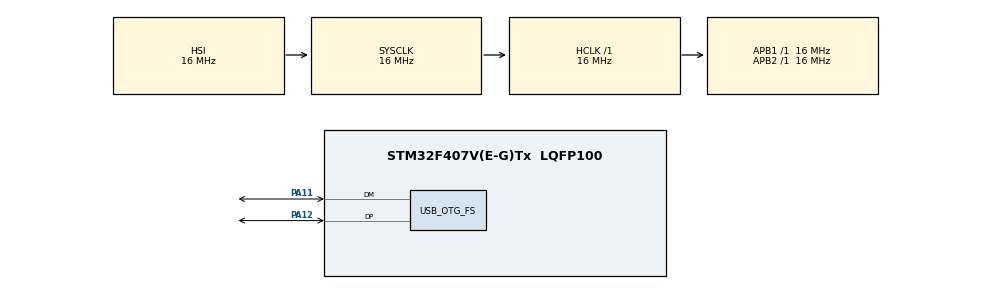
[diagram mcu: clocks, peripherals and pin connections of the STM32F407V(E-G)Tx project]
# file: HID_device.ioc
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Mcu.Family=STM32F4
Mcu.Name=STM32F407V(E-G)Tx
Mcu.Package=LQFP100
NVIC.OTG_FS_IRQn=true\:0\:0\:false\:false\:true
NVIC.PriorityGroup=NVIC_PRIORITYGROUP_4
PA11.Mode=Device_Only
PA11.Signal=USB_OTG_FS_DM
PA12.Mode=Device_Only
PA12.Signal=USB_OTG_FS_DP
PH0-OSC_IN.Mode=HSE-External-Oscillator
PH0-OSC_IN.Signal=RCC_OSC_IN
PH1-OSC_OUT.Mode=HSE-External-Oscillator
PH1-OSC_OUT.Signal=RCC_OSC_OUT
ProjectManager.HeapSize=0x200
ProjectManager.StackSize=0x400
ProjectManager.TargetToolchain=SW4STM32
RCC.48MHZClocksFreq_Value=48000000
RCC.AHBFreq_Value=16000000
RCC.APB1Freq_Value=16000000
RCC.APB2Freq_Value=16000000
RCC.CortexFreq_Value=16000000
RCC.HSE_VALUE=25000000
RCC.HSI_VALUE=16000000
RCC.LSE_VALUE=32768
RCC.PLLM=15
RCC.PLLN=144
RCC.PLLQ=5
RCC.SYSCLKFreq_VALUE=16000000
RCC.VCOOutputFreq_Value=240000000
USB_DEVICE.CLASS_NAME-HID_FS=HID
USB_DEVICE.USBD_HandleTypeDef-HID_FS=hUsbDeviceFS
USB_DEVICE.VirtualMode-HID_FS=Hid
USB_DEVICE.VirtualModeFS=Hid_FS
USB_OTG_FS.VirtualMode=Device_Only
VP_USB_DEVICE_VS_USB_DEVICE_HID_FS.Mode=HID_FS
board=HID_device

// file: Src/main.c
/**
  ******************************************************************************
  * File Name          : main.c
  * Description        : Main program body
  ******************************************************************************
  *
  * COPYRIGHT(c) 2016 STMicroelectronics
  *
  * Redistribution and use in source and binary forms, with or without modification,
  * are permitted provided that the following conditions are met:
  *   1. Redistributions of source code must retain the above copyright notice,
  *      this list of conditions and the following disclaimer.
  *   2. Redistributions in binary form must reproduce the above copyright notice,
  *      this list of conditions and the following disclaimer in the documentation
  *      and/or other materials provided with the distribution.
  *   3. Neither the name of STMicroelectronics nor the names of its contributors
  *      may be used to endorse or promote products derived from this software
  *      without specific prior written permission.
  *
  * THIS SOFTWARE IS PROVIDED BY THE COPYRIGHT HOLDERS AND CONTRIBUTORS "AS IS"
  * AND ANY EXPRESS OR IMPLIED WARRANTIES, INCLUDING, BUT NOT LIMITED TO, THE
  * IMPLIED WARRANTIES OF MERCHANTABILITY AND FITNESS FOR A PARTICULAR PURPOSE ARE
  * DISCLAIMED. IN NO EVENT SHALL THE COPYRIGHT HOLDER OR CONTRIBUTORS BE LIABLE
  * FOR ANY DIRECT, INDIRECT, INCIDENTAL, SPECIAL, EXEMPLARY, OR CONSEQUENTIAL
  * DAMAGES (INCLUDING, BUT NOT LIMITED TO, PROCUREMENT OF SUBSTITUTE GOODS OR
  * SERVICES; LOSS OF USE, DATA, OR PROFITS; OR BUSINESS INTERRUPTION) HOWEVER
  * CAUSED AND ON ANY THEORY OF LIABILITY, WHETHER IN CONTRACT, STRICT LIABILITY,
  * OR TORT (INCLUDING NEGLIGENCE OR OTHERWISE) ARISING IN ANY WAY OUT OF THE USE
  * OF THIS SOFTWARE, EVEN IF ADVISED OF THE POSSIBILITY OF SUCH DAMAGE.
  *
  ******************************************************************************
  */
#include "stm32f4xx_hal.h"
#include "usb_device.h"
#include "gpio.h"

/* USER CODE BEGIN PV */
/* Private variables ---------------------------------------------------------*/

/* USER CODE END PV */

void SystemClock_Config(void);

/* USER CODE BEGIN PFP */
/* Private function prototypes -----------------------------------------------*/

/* USER CODE END PFP */

int main(void)
{

  /* MCU Configuration----------------------------------------------------------*/

  /* Reset of all peripherals, Initializes the Flash interface and the Systick. */
  HAL_Init();

  /* Configure the system clock */
  SystemClock_Config();

  /* Initialize all configured peripherals */
  MX_GPIO_Init();
  MX_USB_DEVICE_Init();

  /* USER CODE BEGIN 2 */
  	  uint8_t i[4];
  /* USER CODE END 2 */

  /* Infinite loop */
  /* USER CODE BEGIN WHILE */
  while (1)
  {
	  i[0]= 0x01;
	 	  i[1]= 0x32;
	 	  i[2]= 0x00;
	 	  i[3]= 0x00;

	 	  USBD_HID_SendReport(&hUsbDeviceFS,i,4);
	  	 HAL_Delay(100);
	  	  i[0]= 0x01;
	  	  i[1]= 0x00;
	  	  i[2]= 0x01;
	  	  i[3]= 0x00;

	  	  USBD_HID_SendReport(&hUsbDeviceFS,i,4);
	  	  HAL_Delay(100);
	  	 	  i[0]= 0x01;
	  	 	  i[1]= 0xCE;
	  	 	  i[2]= 0x00;
	  	 	  i[3]= 0x00;

	  	  USBD_HID_SendReport(&hUsbDeviceFS,i,4);
	  	  HAL_Delay(100);

  /* USER CODE END WHILE */

  }

}

/** System Clock Configuration
*/
void SystemClock_Config(void)
{

  RCC_OscInitTypeDef RCC_OscInitStruct;
  RCC_ClkInitTypeDef RCC_ClkInitStruct;

  __HAL_RCC_PWR_CLK_ENABLE();

  __HAL_PWR_VOLTAGESCALING_CONFIG(PWR_REGULATOR_VOLTAGE_SCALE1);

  RCC_OscInitStruct.OscillatorType = RCC_OSCILLATORTYPE_HSI|RCC_OSCILLATORTYPE_HSE;
  RCC_OscInitStruct.HSEState = RCC_HSE_ON;
  RCC_OscInitStruct.HSIState = RCC_HSI_ON;
  RCC_OscInitStruct.HSICalibrationValue = 16;
  RCC_OscInitStruct.PLL.PLLState = RCC_PLL_ON;
  RCC_OscInitStruct.PLL.PLLSource = RCC_PLLSOURCE_HSE;
  RCC_OscInitStruct.PLL.PLLM = 15;
  RCC_OscInitStruct.PLL.PLLN = 144;
  RCC_OscInitStruct.PLL.PLLP = RCC_PLLP_DIV2;
  RCC_OscInitStruct.PLL.PLLQ = 5;
  HAL_RCC_OscConfig(&RCC_OscInitStruct);

  RCC_ClkInitStruct.ClockType = RCC_CLOCKTYPE_HCLK|RCC_CLOCKTYPE_SYSCLK
                              |RCC_CLOCKTYPE_PCLK1|RCC_CLOCKTYPE_PCLK2;
  RCC_ClkInitStruct.SYSCLKSource = RCC_SYSCLKSOURCE_HSI;
  RCC_ClkInitStruct.AHBCLKDivider = RCC_SYSCLK_DIV1;
  RCC_ClkInitStruct.APB1CLKDivider = RCC_HCLK_DIV1;
  RCC_ClkInitStruct.APB2CLKDivider = RCC_HCLK_DIV1;
  HAL_RCC_ClockConfig(&RCC_ClkInitStruct, FLASH_LATENCY_0);

  HAL_SYSTICK_Config(HAL_RCC_GetHCLKFreq()/1000);

  HAL_SYSTICK_CLKSourceConfig(SYSTICK_CLKSOURCE_HCLK);

  /* SysTick_IRQn interrupt configuration */
  HAL_NVIC_SetPriority(SysTick_IRQn, 0, 0);
}

/************************ (C) COPYRIGHT STMicroelectronics *****END OF FILE****/
